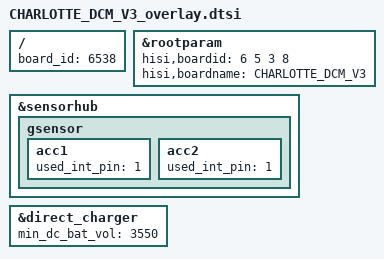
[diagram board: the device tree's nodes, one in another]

/**
 * Copyright (C) 2014 Hisilicon Ltd.
 *
 *  This program is free software; you can redistribute it and/or modify
 *  it under the terms of the GNU General Public License version 2 as
 *  publishhed by the Free Software Foundation.
 */

/include/ "CHARLOTTE_DCM_V2_overlay.dtsi"
/include/ "CHARLOTTE_DCM_V3_overlay_module_amba.dts"

/ {
        board_id = <6538>;
};

&rootparam {
    hisi,boardid = <6 5 3 8>;
    hisi,boardname = "CHARLOTTE_DCM_V3";
};


&sensorhub {
	gsensor {
		acc1 {
			used_int_pin =<1>;
		};
		acc2 {
			used_int_pin =<1>;
		};
	};
};
&direct_charger {
	min_dc_bat_vol = <3550>;
};
